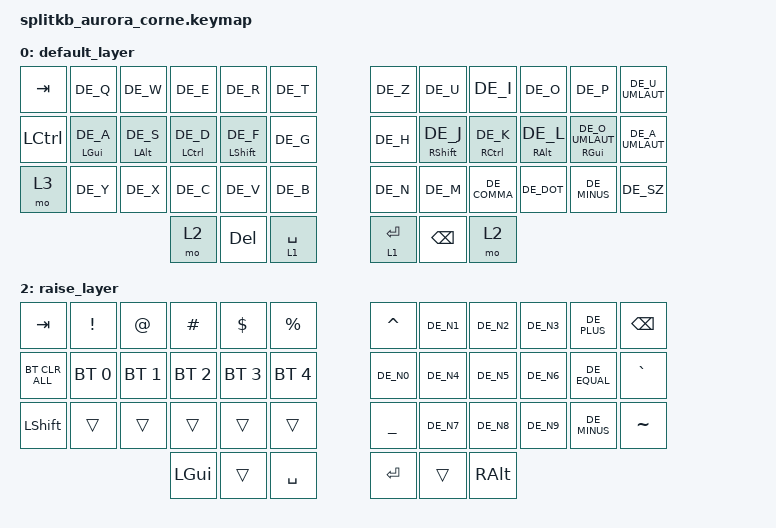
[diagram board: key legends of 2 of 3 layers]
/*Copyright (c) 2020 The ZMK Contributors SPDX-License-Identifier: MIT */

#include <behaviors.dtsi>
#include <dt-bindings/zmk/keys.h>
#include <dt-bindings/zmk/bt.h>
#include "keys_de.h"



/ {
        keymap {
                compatible = "zmk,keymap";

                default_layer {
// -----------------------------------------------------------------------------------------
// |  TAB |  Q  |  W  |  E  |  R  |  T  |   |  Y  |  U   |  I  |  O  |  P  | BSPC |
// | CTRL |  A  |  S  |  D  |  F  |  G  |   |  H  |  J   |  K  |  L  |  ;  |  '   |
// | SHFT |  Z  |  X  |  C  |  V  |  B  |   |  N  |  M   |  ,  |  .  |  /  | ESC  |
//                    | GUI | LWR | SPC |   | ENT | RSE  | ALT |
                        bindings = <
   &kp TAB   &kp DE_Q &kp DE_W &kp DE_E &kp DE_R &kp DE_T                                       &kp DE_Z &kp DE_U  &kp DE_I     &kp DE_O   &kp DE_P    &kp DE_U_UMLAUT
   &kp LCTRL &mt LGUI DE_A &mt LALT DE_S &mt LCTRL DE_D &mt LSHIFT DE_F &kp DE_G                &kp DE_H &mt RSHIFT DE_J &mt RCTRL DE_K &mt RALT DE_L &mt RGUI DE_O_UMLAUT &kp DE_A_UMLAUT 
   &mo 3 &kp DE_Y &kp DE_X &kp DE_C &kp DE_V &kp DE_B                                           &kp DE_N &kp DE_M  &kp DE_COMMA &kp DE_DOT &kp DE_MINUS &kp DE_SZ
                  &mo 2 &kp DEL &lt 1 SPACE                                                     &lt 1 RET &kp BSPC &mo 2
                        >;
                };
                lower_layer {
// -----------------------------------------------------------------------------------------
// |  TAB |  1  |  2  |  3  |  4  |  5  |   |  6  |  7  |  8  |  9  |  0  | BSPC |
// | BTCLR| BT1 | BT2 | BT3 | BT4 | BT5 |   | LFT | DWN |  UP | RGT |     |      |
// | SHFT |     |     |     |     |     |   |     |     |     |     |     |      |
//                    | GUI |     | SPC |   | ENT |     | ALT |
                        bindings = <
   &kp CAPS  &kp N1  &kp N2  &kp N3  &kp  DE_BSLH  &kp DE_SLASH                 &kp DE_DQT   &kp DE_SQT  &kp DE_STAR &kp DE_QMARK  &kp DE_GRAVE &kp BSPC
   &kp RA(N7) &kp RA(N0) &kp LS(N8) &kp LS(N9) &kp RA(N8) &kp RA(N9)                &kp LEFT &kp DOWN &kp UP &kp RIGHT &trans &kp PERIOD
   &kp LSHFT  &trans       &trans       &trans       &trans &trans              &kp DE_HASH   &kp DE_TILDE   &kp DE_LT   &kp DE_LT &trans    &trans &trans
                                    &kp LGUI &trans &kp DE_SPACE          &kp RET  &trans   &kp RALT
                        >;
                };

                raise_layer {
// -----------------------------------------------------------------------------------------
// |  TAB |  !  |  @  |  #  |  $  |  %  |   |  ^  |  &  |  *  |  (  |  )  | BSPC |
// | CTRL |     |     |     |     |     |   |  -  |  =  |  [  |  ]  |  \  |  `   |
// | SHFT |     |     |     |     |     |   |  _  |  +  |  {  |  }  | "|" |  ~   |
//                    | GUI |     | SPC |   | ENT |     | ALT |
                        bindings = <
   &kp  TAB  &kp EXCL &kp AT &kp HASH &kp DLLR &kp PRCNT                                        &kp CARET &kp DE_N1  &kp DE_N2 &kp DE_N3 &kp DE_PLUS &kp BSPC
   &bt BT_CLR_ALL &bt BT_SEL 0 &bt BT_SEL 1 &bt BT_SEL 2 &bt BT_SEL 3 &bt BT_SEL 4                  &kp DE_N0 &kp DE_N4 &kp DE_N5 &kp DE_N6 &kp DE_EQUAL &kp GRAVE
   &kp LSHFT &trans   &trans &trans   &trans   &trans                                           &kp UNDER &kp DE_N7  &kp DE_N8  &kp DE_N9 &kp DE_MINUS &kp TILDE
                             &kp LGUI &trans   &kp SPACE                                        &kp RET   &trans    &kp RALT
                        >;
                };
        };
};
